# NAVSS0_CPTS register map
Vendor: Texas Instruments
Peripheral module from a debugger description file (folder am65x).
Registers are 32-bit, read-write, reset 0x0 unless marked. A register's access mark holds for its fields unless they carry their own. Offsets are as the file gives them; lines under a group give offsets from that group; [hi:lo] are bit positions; {n}, {i} and the like mark numbered series; 'fields as' and 'values as' point back to an identical list; <NAME> marks a mode.

## NAVSS0_CPTS
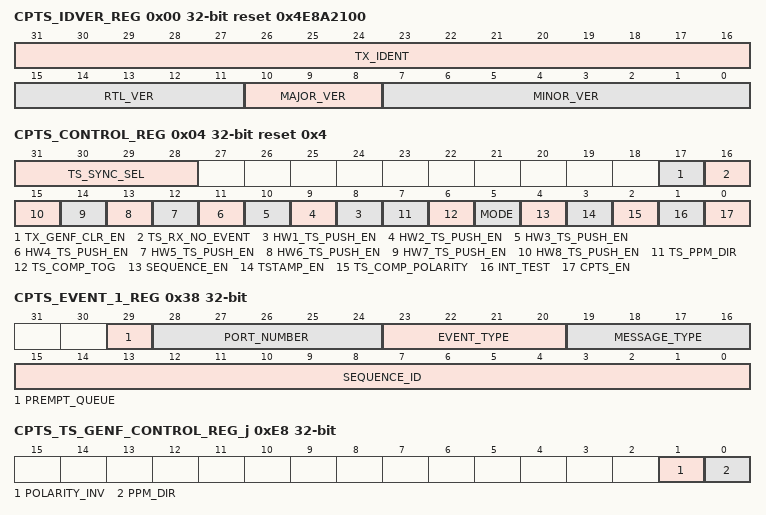
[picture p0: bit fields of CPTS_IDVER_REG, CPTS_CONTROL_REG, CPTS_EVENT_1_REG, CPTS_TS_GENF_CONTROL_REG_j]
0x00 CPTS_IDVER_REG ro reset 0x4E8A2100 (reset mask 0xFFFFFF00) — Identification and Version Register
  [31:16] TX_IDENT — Identification value
  [15:11] RTL_VER — RTL version value
  [10:8] MAJOR_VER — Major version value
  [7:0] MINOR_VER — Minor version value SR2.0: Bh SR1.0: 9h
0x04 CPTS_CONTROL_REG reset 0x4 — Time Sync Control Register
  [31:28] TS_SYNC_SEL — TS_SYNC output timestamp counter bit select0000 – TS_SYNC disabled 0001 0001..1111 - TS_SYNC is timestamp counter bits 31 (1111) down to 17 (0001)
  [17] TX_GENF_CLR_EN — GENF (and ESTF) Clear Enable. 0 - A TS_GENFn output is not cleared when the associated CPTS_TS_GENF_LENGTH_REG_j[31:0] LENGTH field is cleared to zero. 1 - A TS_GENFn output is cleared when the associated CPTS_TS_GENF_LENGTH_REG_j[31:0] LENGTH field is cleared to zero.
  [16] TS_RX_NO_EVENT — Timestamp Ethernet Receive produces no events. 0 - Ethernet receive timesync events enabled 1 - Ethernet receive timesync events disabled
  [n+7] HW{n}_TS_PUSH_EN (n=1..8) — Hardware push {n} enable
  [7] TS_PPM_DIR — Timestamp PPM Direction0 – Increase the time_stamp[63:0] value by the PPM value 1 – Decrease the time_stamp[63:0] value by the PPM value
  [6] TS_COMP_TOG — Timestamp Compare Toggle mode: 0=TS_COMP is in non-toggle mode 1=TS_COMP is in toggle mode
  [5] MODE — Timestamp mode 0 – The timestamp is 32-bits with the upper 32-bits forced to zero. 1 – The timestamp is 64-bits.
  [4] SEQUENCE_EN — Sequence Enable0 – The timestamp value increments with the selected RFTCLK 1 - The timestamp for received packets is the sequence number of the received packet (first packet is 1, second packet is 2, etc).
  [3] TSTAMP_EN — Host Receive Timestamp Enable0 – Timestamps are disabled on received packets to host 1 – Timestamps enabled on received packets to host (cpts_en must be set)
  [2] TS_COMP_POLARITY — TS_COMP polarity0 – TS_COMP is asserted low 1 – TS_COMP is asserted high
  [1] INT_TEST — Interrupt testWhen set, this bit allows the raw interrupt to be written to facilitate interrupt test.
  [0] CPTS_EN — Time sync enableWhen disabled (cleared to zero), the RCLK domain is held in reset.
0x08 CPTS_RFTCLK_SEL_REG — Added RFTCLK_SEL Register Bit Field Description in Section Time Sync Module RFTCLK Select Register
  [4:0] RFTCLK_SEL — Reference clock select. This bit field is used to control an external multiplexer that selects one out of 8 clocks for time sync reference. 0h: Selects CPSWHSDIV_CLKOUT2 clock The RFTCLK_SEL value can be written only when the [0] CPTS_EN and [3] TSTAMP_EN bits are cleared to zero in the
0x0C CPTS_TS_PUSH_REG wo — Time Stamp Event Push Register
  [0] TS_PUSH — Time stamp event pushWhen a logic high is written to this bit a time stamp event is pushed onto the event FIFO. The time stamp value is the time of the write of this register, not the time of the event read. The time stamp value can then be read on interrupt via the event registers. Software should not push a second time stamp event onto the event FIFO until the first time stamp value has been read from the event FIFO (there should be only one time stamp event in the event FIFO at any given time).
0x10 CPTS_TS_LOAD_VAL_REG — Time Stamp Load Low Value Register
  [31:0] TS_LOAD_VAL — Time stamp load low valueWriting the ts_load_en bit causes ts_load[63:0] to be written into the time stamp. The time stamp value is read by initiating a time stamp push event, not by reading this register. When reading this register, the value read is not the time stamp, but is the value that was last written to this register.
0x14 CPTS_TS_LOAD_EN_REG wo — Time Stamp Load Enable Register
  [0] TS_LOAD_EN — Time stamp load enableWriting a one to this bit enables the time stamp value to be written with the value in ts_load[63:0]. This bit is write only and will be cleared by the hardware after one clock. The upper 32-bits of the timestamp are forced to zero in 32-bit mode.
0x18 CPTS_TS_COMP_VAL_REG — Time Stamp Comparison Low Value Register
  [31:0] TS_COMP_VAL — Time stamp comparison low valueWriting a non-zero value to the TS_Comp_Length[31:0] register causes a pulse of TS_Comp_Length RCLK periods on the TS_COMP output and a comparison event when the time_stamp counter value is equivalent to ts_comp_val.
0x1C CPTS_TS_COMP_LEN_REG — Time Stamp Comparison Length Register
  [31:0] TS_COMP_LENGTH — Time stamp comparison lengthWriting a non-zero value to this field enables the time stamp comparison event and output. This value should be zero when the TS_Comp_Low and TS_Comp_High registers are written.
0x20 CPTS_INTSTAT_RAW_REG — Interrupt Status Register Raw
  [0] TS_PEND_RAW — TS_PEND_RAW int read (before enable)Writable when int_test = 1. A one in this bit indicates that there are one or more events in the event FIFO.
0x24 CPTS_INTSTAT_MASKED_REG ro — Interrupt Status Register Masked
  [0] TS_PEND — TS_PEND masked interrupt read (after enable)
0x28 CPTS_INT_ENABLE_REG — Interrupt Enable Register
  [0] TS_PEND_EN — TS_PEND masked interrupt enable
0x2C CPTS_TS_COMP_NUDGE_REG — Time Stamp Comparison Nudge Register
  [7:0] NUDGE — This 2s complement number is added to the ts_comp_length value to increase or decrease the TS_COMP length by the nudge amountOnly a single high or low time is adjusted and the ts_comp_nudge value is cleared to zero when the nudge has occurred.
0x30 CPTS_EVENT_POP_REG wo — Event Pop Register
  [0] EVENT_POP — Event popWhen a logic high is written to this bit an event is popped off the event FIFO. The event FIFO pop occurs as part of the interrupt process after the event has been read from the Event_0-3 registers. Popping an event discards the event and causes the next event, if any, to be moved to the top of the FIFO ready to be read by software on interrupt.
0x34 CPTS_EVENT_0_REG ro — Event 0 Register
  [31:0] TIME_STAMP — Time StampThe timestamp is valid for transmit, receive, and time stamp push event types. The timestamp value is not valid for counter roll event types.
0x38 CPTS_EVENT_1_REG ro — Event 1 Register
  [29] PREMPT_QUEUE — Prempt QUEUE0 – The packet was received/transmitted on the express queue. 1 – The packet was received/transmitted on the prempt queue.
  [28:24] PORT_NUMBER — Port numberindicates the port number (encoded) of an Ethernet event or the encoded hardware timestamp number.
  [23:20] EVENT_TYPE — Event type0000 – Time Stamp Push Event 0001 – Time Stamp Rollover Event 0010 – Time Stamp Half Rollover Event 0011 – Hardware Time Stamp Push Event 0100 – Ethernet Receive Event 0101 – Ethernet Transmit Event 0110 – Time Stamp Compare Event 0111 – Host Transmit Event 1000 1111 reserved
  [19:16] MESSAGE_TYPE — Message typeThe message type value that was contained in an Ethernet transmit or receive time sync packet. This field is valid only for Ethernet transmit or receive events.
  [15:0] SEQUENCE_ID — Sequence IDThe 16-bit sequence id is the value that was contained in an Ethernet transmit or receive time sync packet. This field is valid only for Ethernet transmit or receive events.
0x3C CPTS_EVENT_2_REG ro — Event 2 Register
  [7:0] DOMAIN — DomainThe 8-bit domain is the value that was contained in an Ethernet transmit or receive time sync packet. This field is valid only for Ethernet transmit or receive events.
0x40 CPTS_EVENT_3_REG ro — Event 3 Register
  [31:0] TIME_STAMP — Time StampThe timestamp upper 32-bits are valid for transmit, receive, and time stamp push event types. This value is zero in 32-bit mode.
0x44 CPTS_TS_LOAD_HIGH_VAL_REG — Time Stamp Load High Value Register
  [31:0] TS_LOAD_VAL — Time stamp load high valueWriting the ts_load_en bit causes the value contained in this register (and the ts_load[63:0]) to be written into the time stamp. The time stamp value is read by initiating a time stamp push event, not by reading this register. When reading this register, the value read is not the time stamp, but is the value that was last written to this register. This value is unused in 32-bit mode
0x48 CPTS_TS_COMP_HIGH_VAL_REG — Time Stamp Comparison High Value Register
  [31:0] TS_COMP_HIGH_VAL — Time stamp comparison high valueWriting a non-zero value to the TS_Comp_Length[31:0] register causes a pulse of TS_Comp_Length RCLK periods on the TS_COMP output and a comparison event when the time_stamp counter value is equivalent to ts_comp_val[63:0]. This value is unused in 32-bit mode. The upper 32-bits in this register should be written before the lower 32-bits in the TS_Comp_Low register.
0x4C CPTS_TS_ADD_VAL_REG — TS Add Value Register
  [2:0] ADD_VAL — Add ValueAdd Value is added to 1 to comprise the timestamp increment value. The timestamp increment value is added to the current timestamp (time_stamp[63:0]) on each RCLK. The timestamp increment value can be adjusted by nudge and ppm also. The ts_add_val[2:0] value may be non-zero in 64-bit mode only.
0x50 CPTS_TS_PPM_LOW_VAL_REG — Time Stamp PPM Low Value Register
  [31:0] TS_PPM_LOW_VAL — Time stamp PPM Low valueThe 64-bit PPM value takes effect when this low value is written. The high value should be written first. Note: There should be at least 10 clocks in between writes to the low register to ensure that the previous operation has been seen
0x54 CPTS_TS_PPM_HIGH_VAL_REG — Time Stamp PPM High Value Register
  [9:0] TS_PPM_HIGH_VAL — Time stamp PPM High valueThis value should be written first (before the low value is written). The minimum value of the ts_ppm is 0x400 (all 42 bits).
0x58 CPTS_TS_NUDGE_VAL_REG — Time Stamp Nudge Value Register
  [7:0] TS_NUDGE_VAL — Time stamp Nudge valueThis two’s complement number is added to the time_stamp[63:0] value to increase or decrease the timestamp value by the ts_nudge amount. The ts_nudge value is cleared to zero when the nudge has occurred.
0xE0 CPTS_TS_GENF_COMP_LOW_REG_j — Time Stamp Generate Function Comparison Low Value Offset = E0h + (j * 20h); where j = 0h to 5h
  [31:0] COMP_LOW — Time Stamp Generate Function Comparison Low ValueThis value should be written after the upper 32-bits. The ts_GENFn_comp high and low should only be written when the ts_GENFn_length value is zero.
0xE4 CPTS_TS_GENF_COMP_HIGH_REG_j — Time Stamp Generate Function Comparison high Value Offset = E4h + (j * 20h); where j = 0h to 5h
  [31:0] COMP_HIGH — Time Stamp Generate Function Comparison High ValueThis value should be written before the lower 32-bits are written. The ts_GENFn_comp high and low should only be written when the ts_GENFn_length value is zero.
0xE8 CPTS_TS_GENF_CONTROL_REG_j — Time Stamp Generate Function Control Offset = E8h + (j * 20h); where j = 0h to 5h
  [1] POLARITY_INV — Time Stamp Generate Function Polarity Invert0 – The output TS_GENFn signal asserts high 1 – The output TS_GENFn signal asserts low
  [0] PPM_DIR — Time Stamp Generate Function PPM Direction0 – A single RCLK is added to the generate function counter at the PPM rate which has the effect of decreasing the generate function frequency by the PPM amount. 1 – A single RCLK is subtracted from the generate function counter at the PPM rate which has the effect of increasing the generate function frequency by the PPM amount.
0xEC CPTS_TS_GENF_LENGTH_REG_j — Time Stamp Generate Function Length Value Offset = ECh + (j * 20h); where j = 0h to 5h
  [31:0] LENGTH — Time Stamp Generate Function Length ValueThe minimum value is decimal 5
0xF0 CPTS_TS_GENF_PPM_LOW_REG_j — Time Stamp Generate Function PPM Low Value Offset = F0h + (j * 20h); where j = 0h to 5h
  [31:0] PPM_LOW — Time Stamp Generate Function PPM Low ValueThe 64-bit PPM value takes effect when this low value is written. The high value should be written first
0xF4 CPTS_TS_GENF_PPM_HIGH_REG_j — Time Stamp Generate Function PPM High Value Offset = F4h + (j * 20h); where j = 0h to 5h
  [9:0] PPM_HIGH — Time Stamp Generate Function PPM High ValueThis value should be written first (before the low value is written).
0xF8 CPTS_TS_GENF_NUDGE_REG_j — Time Stamp Generate Function Nudge Value Offset = F8h + (j * 20h); where j = 0h to 5h
  [7:0] NUDGE — Time Stamp Generate Function Nudge ValueThis two’s complement number is added to the generate counter value to increase or decrease the length by the ts_genfN_nudge amount. Only a single high or low time is adjusted and the ts_genfN_nudge value is cleared to zero when the nudge has occurred.
0x200 CPTS_TS_ESTF_COMP_LOW_REG — Time Stamp ESTF Generate Function Comparison Low Value
  [31:0] COMP_LOW — Time Stamp ESTF Generate Function Comparison Low ValueThis value should be written after the upper 32-bits. The ts_ESTFn_comp high and low should only be written when the ts_ESTFn_length value is zero.
0x204 CPTS_TS_ESTF_COMP_HIGH_REG — Time Stamp ESTF Generate Function Comparison high Value
  [31:0] COMP_HIGH — Time Stamp ESTF Generate Function Comparison High ValueThis value should be written before the lower 32-bits are written. The ts_ESTFn_comp high and low should only be written when the ts_ESTFn_length value is zero
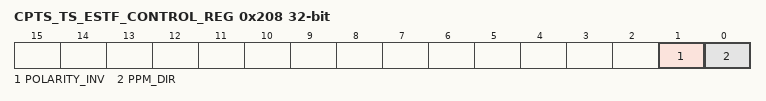
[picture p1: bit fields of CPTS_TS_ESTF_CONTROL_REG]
0x208 CPTS_TS_ESTF_CONTROL_REG — Time Stamp ESTF Generate Function Control
  [1] POLARITY_INV — Time Stamp ESTF Generate Function Polarity Invert 0 – The output TS_ESTFn signal asserts low 1 – The output TS_ESTFn signal asserts high
  [0] PPM_DIR — Time Stamp ESTF Generate Function PPM Direction 0 – A single RCLK is added to the generate function counter at the PPM rate which has the effect of decreasing the generate function frequency by the PPM amount. 1 – A single RCLK is subtracted from the generate function counter at the PPM rate which has the effect of increasing the generate function frequency by the PPM amount.
0x20C CPTS_TS_ESTF_LENGTH_REG — Time Stamp ESTF Generate Function Length Value
  [31:0] LENGTH
0x210 CPTS_TS_ESTF_PPM_LOW_REG — Time Stamp ESTF Generate Function PPM Low Value
  [31:0] PPM_LOW — Time Stamp ESTF Generate Function PPM Low ValueThe 64-bit PPM value takes effect when this low value is written. The high value should be written first.
0x214 CPTS_TS_ESTF_PPM_HIGH_REG — Time Stamp ESTF Generate Function PPM High Value
  [9:0] PPM_HIGH — Time Stamp ESTF Generate Function PPM High ValueThis value should be written first (before the low value is written).
0x218 CPTS_TS_ESTF_NUDGE_REG — Time Stamp ESTF Generate Function Nudge Value
  [7:0] NUDGE — Time Stamp ESTF Generate Function Nudge ValueThis two’s complement number is added to the generate counter value to increase or decrease the length by the ts_estfN_nudge amount. Only a single high or low time is adjusted and the ts_estfN_nudge value is cleared to zero when the nudge has occurred.
